AUTOSAR XML (schema 4-3-0)
# \copyright BMW AG 2015 - 2017
package /BMW/Platform/SysTime/SwComponentTypes
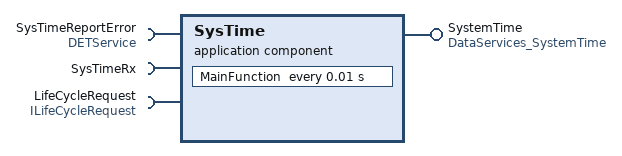
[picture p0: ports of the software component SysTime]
  application sw component type SysTime
    provide port SystemTime: provided-interface=DataServices_SystemTime
    provide/require port LifeCycle: mode-switch-sender-com-spec{enhanced-mode-api=true, mode-group=Mode, queue-length=2}, provided-required-interface=ILifeCycle
    require port SysTimeReportError: required-interface=DETService
    require port SysTimeRx: nonqueued-receiver-com-spec{data-element=timeSignal, init-value=0}, required-interface=SysTimeRx
    require port LifeCycleRequest: nonqueued-receiver-com-spec{data-element=requestMode, init-value=2}, required-interface=ILifeCycleRequest
    behavior Internal_SysTime: data-type-mapping=DataTMappingSet1, handle-termination-and-restart=NO-SUPPORT
      exclusive area SysTimeGetTimeArea
      timing event TimingEvent: disabled-mode=[LifeCycle.Mode.SYSTIME_INITIALIZED, LifeCycle.Mode.SYSTIME_STOPPED], start-on-event=MainFunction, period=0.01
      data received event LifeCycleRequest: start-on-event=LifeCycleHandler, data=LifeCycleRequest.requestMode
      data received event SysTimeRx: disabled-mode=[LifeCycle.Mode.SYSTIME_INITIALIZED, LifeCycle.Mode.SYSTIME_STOPPED], start-on-event=ReceiveSignal, data=SysTimeRx.timeSignal
      operation invoked event OpInvokedEventReadDID: start-on-event=ReadDataSystemTime, operation=SystemTime.ReadData
      4 x runnable:
        MainFunction: can-enter-exclusive-area=SysTimeGetTimeArea, symbol=SysTime_MainFunction
        LifeCycleHandler: mode-access-point=LifeCycle.Mode, symbol=SysTime_LifeCycleHandler
          data-read-access:
            access requestedMode: accessed-variable=LifeCycleRequest.requestMode
          mode switch point LifeCycle: mode-group=LifeCycle.Mode
          sync call sscp_DetError: operation=SysTimeReportError.ReportError, timeout=0.0
        ReceiveSignal: can-enter-exclusive-area=SysTimeGetTimeArea, can-be-invoked-concurrently=true, symbol=SysTime_ReceiveSignal
          data-receive-point-by-arguments:
            access VariableAccess_timeSignal: accessed-variable=SysTimeRx.timeSignal
        ReadDataSystemTime: can-enter-exclusive-area=SysTimeGetTimeArea, can-be-invoked-concurrently=true, symbol=SysTime_GetSystemTime
          sync call sscp_DetError: operation=SysTimeReportError.ReportError, timeout=0.0
      swc service dependency SysTimeDiagnosticValueServiceNeeds: assigned-ports=role-based-port-assignment={port-prototype=SystemTime, role=DataServices}
        service-needs:
          diagnostic value needs sn_DiagnosticValueServiceNeeds: data-length=4, diagnostic-value-access=READ-ONLY, did-number=5889
      swc service dependency SysTimeDiagnosticEventManagerService: assigned-ports=role-based-port-assignment={port-prototype=SystemTime, role=CSDataServices}
        service-needs:
          diagnostic event manager needs sn_SysTimeDiagnosticEventManagerService
package /BMW/Platform/SysTime/SwcImplementations
  swc implementation ImplementationSysTime: programming-language=C, sw-version=5.0.3, vendor-id=5, behavior=Internal_SysTime
    code-descriptors:
      code Code1: artifact-descriptors=autosar-engineering-object={short-label=-, category=-}
    resource consumption ResConsumption1
